VERSION ""

NS_ :

BS_:

BU_: XXX

BO_ 1 DOORS_STATUS: 8 XXX
 SG_ DOOR_LOCK_STATUS : 31|16@0+ (1,0) [0|65535] "" XXX

BO_ 3 STEERING_SENSORS: 8 XXX
 SG_ STEER_ANGLE : 7|16@0+ (1,0) [-500|500] "deg" XXX

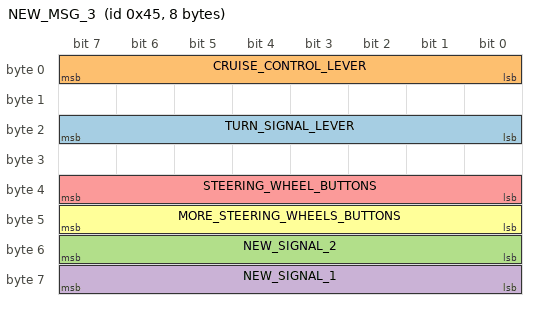
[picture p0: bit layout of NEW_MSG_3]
BO_ 69 NEW_MSG_3: 8 XXX
 SG_ TURN_SIGNAL_LEVER : 16|8@1+ (1,0) [0|255] "" XXX
 SG_ CRUISE_CONTROL_LEVER : 7|8@0+ (1,0) [0|255] "" XXX
 SG_ NEW_SIGNAL_2 : 55|8@0+ (1,0) [0|255] "" XXX
 SG_ NEW_SIGNAL_1 : 63|8@0+ (1,0) [0|255] "" XXX
 SG_ STEERING_WHEEL_BUTTONS : 32|8@1+ (1,0) [0|255] "4 directional, 2 volume control, & 2 phone buttons" XXX
 SG_ MORE_STEERING_WHEELS_BUTTONS : 40|8@1+ (1,0) [0|255] "" XXX

BO_ 115 BRAKE_MODULE: 8 XXX
 SG_ BRAKE_PRESSED : 13|1@0+ (1,0) [0|1] "Some sort of delayed break press" XXX
 SG_ BRAKE_PRESSED_2 : 46|1@0+ (1,0) [0|1] "Actual break press e.g light tap" XXX
